AUTOSAR XML (schema 00044)
package /E40_Platform_System_SystemPackage/Components
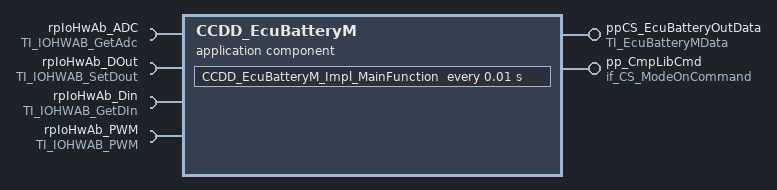
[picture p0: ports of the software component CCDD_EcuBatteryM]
  application sw component type CCDD_EcuBatteryM
    provide port ppCS_EcuBatteryOutData: provided-interface=TI_EcuBatteryMData
      provided-com-specs:
        operation=EcuBatteryM_GetChannelStatus, queue-length=1
        operation=EcuBatteryM_GetDIOStatus, queue-length=1
    provide port pp_CmpLibCmd: server-com-spec{operation=Impl_OnCommand, queue-length=1}, provided-interface=if_CS_ModeOnCommand
    4 x require port:
      rpIoHwAb_ADC: required-com-specs=[GetAsyncRawAdc, GetProcessedAdc, GetSyncRawAdc], required-interface=TI_IOHWAB_GetAdc
      rpIoHwAb_DOut: required-com-specs=[SetOutputGroup, SetOutputPin], required-interface=TI_IOHWAB_SetDout
      rpIoHwAb_Din: required-com-specs=[GetAsyncRawInput, GetInputGroup, GetProcessedInput, GetSyncRawInput], required-interface=TI_IOHWAB_GetDIn
      rpIoHwAb_PWM: required-com-specs=[PwmSetDuty, PwmSetDutyAndPeriod, PwmSetIdeal], required-interface=TI_IOHWAB_PWM
    behavior IB_CCDD_EcuBatteryM
      timing event TECCDD_EcuBatteryM_Impl_MainFunction: start-on-event=CCDD_EcuBatteryM_Impl_MainFunction, period=0.01
      operation invoked event OIE_ppCS_EcuBatteryOutData_EcuBatteryM_GetChannelStatusTrigByEcuBatteryM_GetChannelStatus: start-on-event=EcuBatteryM_GetChannelStatus, operation=ppCS_EcuBatteryOutData.EcuBatteryM_GetChannelStatus
      operation invoked event OIE_ppCS_EcuBatteryOutData_EcuBatteryM_GetDIOStatusTrigByEcuBatteryM_GetDIOStatus: start-on-event=EcuBatteryM_GetDIOStatus, operation=ppCS_EcuBatteryOutData.EcuBatteryM_GetDIOStatus
      operation invoked event OIE_pp_CmpLibCmd_CCDD_EcuBatteryM_Impl_OnCommandTrigByImpl_OnCommand: start-on-event=CCDD_EcuBatteryM_Impl_OnCommand, operation=pp_CmpLibCmd.Impl_OnCommand
      port-api-options:
        enable-take-address=false, indirect-api=false, port=ppCS_EcuBatteryOutData
        enable-take-address=false, indirect-api=false, port=pp_CmpLibCmd
        enable-take-address=false, indirect-api=false, port=rpIoHwAb_ADC
        enable-take-address=false, indirect-api=false, port=rpIoHwAb_DOut
        enable-take-address=false, indirect-api=false, port=rpIoHwAb_Din
        enable-take-address=false, indirect-api=false, port=rpIoHwAb_PWM
      4 x runnable, all with can-be-invoked-concurrently=true:
        CCDD_EcuBatteryM_Impl_MainFunction
          12 x sync call:
            OA_rpIoHwAb_ADC_GetAsyncRawAdc: operation=rpIoHwAb_ADC.GetAsyncRawAdc
            OA_rpIoHwAb_ADC_GetSyncRawAdc: operation=rpIoHwAb_ADC.GetSyncRawAdc
            OA_rpIoHwAb_ADC_GetProcessedAdc: operation=rpIoHwAb_ADC.GetProcessedAdc
            OA_rpIoHwAb_DOut_SetOutputGroup: operation=rpIoHwAb_DOut.SetOutputGroup
            OA_rpIoHwAb_DOut_SetOutputPin: operation=rpIoHwAb_DOut.SetOutputPin
            OA_rpIoHwAb_Din_GetAsyncRawInput: operation=rpIoHwAb_Din.GetAsyncRawInput
            OA_rpIoHwAb_Din_GetProcessedInput: operation=rpIoHwAb_Din.GetProcessedInput
            OA_rpIoHwAb_Din_GetSyncRawInput: operation=rpIoHwAb_Din.GetSyncRawInput
            OA_rpIoHwAb_Din_GetInputGroup: operation=rpIoHwAb_Din.GetInputGroup
            OA_rpIoHwAb_PWM_PwmSetDuty: operation=rpIoHwAb_PWM.PwmSetDuty
            OA_rpIoHwAb_PWM_PwmSetDutyAndPeriod: operation=rpIoHwAb_PWM.PwmSetDutyAndPeriod
            OA_rpIoHwAb_PWM_PwmSetIdeal: operation=rpIoHwAb_PWM.PwmSetIdeal
        EcuBatteryM_GetChannelStatus
        EcuBatteryM_GetDIOStatus
        CCDD_EcuBatteryM_Impl_OnCommand
  swc implementation IMPL_CCDD_EcuBatteryM: behavior=IB_CCDD_EcuBatteryM
